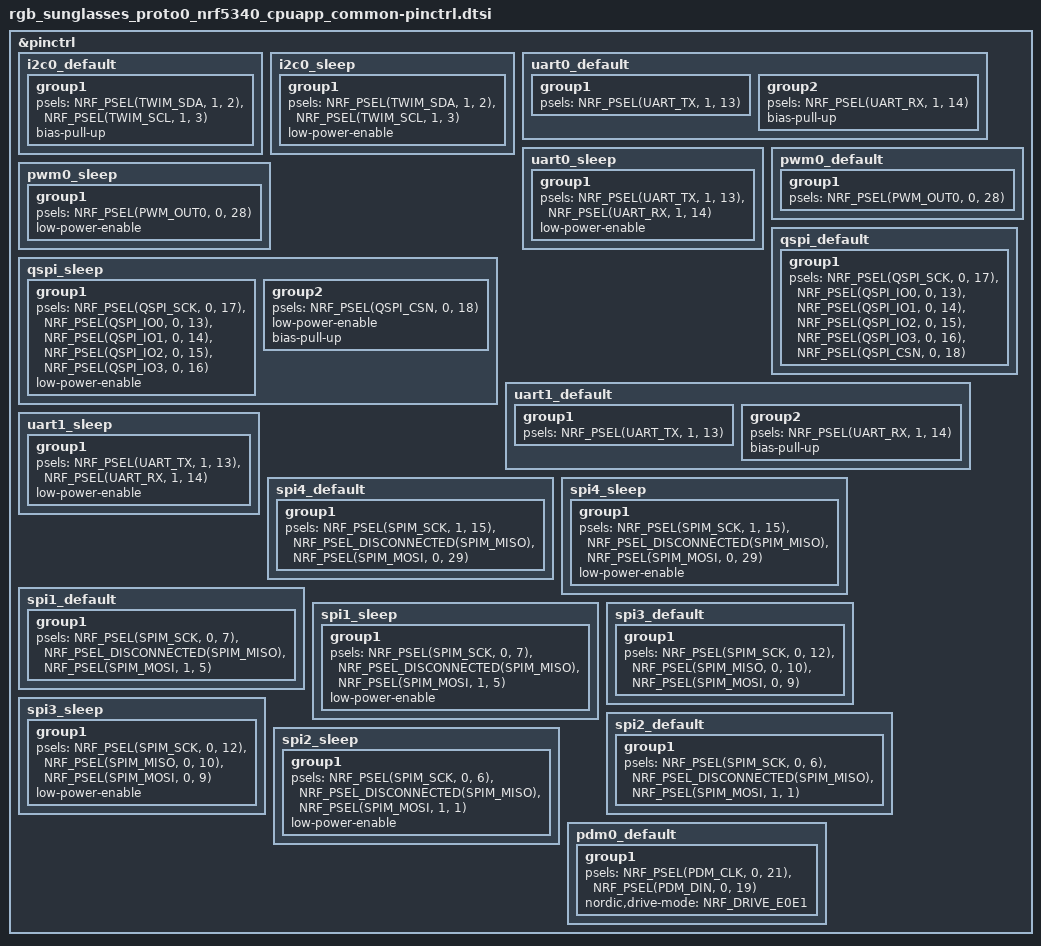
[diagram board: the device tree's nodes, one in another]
/*
 * Copyright (c) 2022 Nordic Semiconductor
 * SPDX-License-Identifier: Apache-2.0
 */

&pinctrl {
	i2c0_default: i2c0_default {
		group1 {
			psels = <NRF_PSEL(TWIM_SDA, 1, 2)>,
				<NRF_PSEL(TWIM_SCL, 1, 3)>;
			bias-pull-up;
		};
	};

	i2c0_sleep: i2c0_sleep {
		group1 {
			psels = <NRF_PSEL(TWIM_SDA, 1, 2)>,
				<NRF_PSEL(TWIM_SCL, 1, 3)>;
			low-power-enable;
		};
	};

	/* Physical UART: P1.13 = TX, P1.14 = RX (no hardware flow control on proto0) */
	uart0_default: uart0_default {
		group1 {
			psels = <NRF_PSEL(UART_TX, 1, 13)>;
		};
		group2 {
			psels = <NRF_PSEL(UART_RX, 1, 14)>;
			bias-pull-up;
		};
	};

	uart0_sleep: uart0_sleep {
		group1 {
			psels = <NRF_PSEL(UART_TX, 1, 13)>,
				<NRF_PSEL(UART_RX, 1, 14)>;
			low-power-enable;
		};
	};

	pwm0_default: pwm0_default {
		group1 {
			psels = <NRF_PSEL(PWM_OUT0, 0, 28)>;
		};
	};

	pwm0_sleep: pwm0_sleep {
		group1 {
			psels = <NRF_PSEL(PWM_OUT0, 0, 28)>;
			low-power-enable;
		};
	};

	qspi_default: qspi_default {
		group1 {
			psels = <NRF_PSEL(QSPI_SCK, 0, 17)>,
				<NRF_PSEL(QSPI_IO0, 0, 13)>,
				<NRF_PSEL(QSPI_IO1, 0, 14)>,
				<NRF_PSEL(QSPI_IO2, 0, 15)>,
				<NRF_PSEL(QSPI_IO3, 0, 16)>,
				<NRF_PSEL(QSPI_CSN, 0, 18)>;
		};
	};

	qspi_sleep: qspi_sleep {
		group1 {
			psels = <NRF_PSEL(QSPI_SCK, 0, 17)>,
				<NRF_PSEL(QSPI_IO0, 0, 13)>,
				<NRF_PSEL(QSPI_IO1, 0, 14)>,
				<NRF_PSEL(QSPI_IO2, 0, 15)>,
				<NRF_PSEL(QSPI_IO3, 0, 16)>;
			low-power-enable;
		};
		group2 {
			psels = <NRF_PSEL(QSPI_CSN, 0, 18)>;
			low-power-enable;
			bias-pull-up;
		};
	};

	/* Secondary UART forwarded to network core via gpio_fwd (P1.13 TX, P1.14 RX) */
	uart1_default: uart1_default {
		group1 {
			psels = <NRF_PSEL(UART_TX, 1, 13)>;
		};
		group2 {
			psels = <NRF_PSEL(UART_RX, 1, 14)>;
			bias-pull-up;
		};
	};

	uart1_sleep: uart1_sleep {
		group1 {
			psels = <NRF_PSEL(UART_TX, 1, 13)>,
				<NRF_PSEL(UART_RX, 1, 14)>;
			low-power-enable;
		};
	};

	spi4_default: spi4_default {
		group1 {
			psels = <NRF_PSEL(SPIM_SCK, 1, 15)>,
				/* MISO disconnected: led_strip_1 (WS2812) is output-only */
				<NRF_PSEL_DISCONNECTED(SPIM_MISO)>,
				<NRF_PSEL(SPIM_MOSI, 0, 29)>;
		};
	};

	spi4_sleep: spi4_sleep {
		group1 {
			psels = <NRF_PSEL(SPIM_SCK, 1, 15)>,
				<NRF_PSEL_DISCONNECTED(SPIM_MISO)>,
				<NRF_PSEL(SPIM_MOSI, 0, 29)>;
			low-power-enable;
		};
	};

	spi1_default: spi1_default {
		group1 {
			psels = <NRF_PSEL(SPIM_SCK, 0, 7)>,
				/* MISO disconnected: led_strip_0 (WS2812) is output-only; P0.19 is now PDM_DIN */
				<NRF_PSEL_DISCONNECTED(SPIM_MISO)>,
				<NRF_PSEL(SPIM_MOSI, 1, 5)>;
		};
	};

	spi1_sleep: spi1_sleep {
		group1 {
			psels = <NRF_PSEL(SPIM_SCK, 0, 7)>,
				<NRF_PSEL_DISCONNECTED(SPIM_MISO)>,
				<NRF_PSEL(SPIM_MOSI, 1, 5)>;
			low-power-enable;
		};
	};

	/* BMI270 IMU: SCK=P0.12, MISO=P0.10, MOSI=P0.09 */
	spi3_default: spi3_default {
		group1 {
			psels = <NRF_PSEL(SPIM_SCK,  0, 12)>,
				<NRF_PSEL(SPIM_MISO, 0, 10)>,
				<NRF_PSEL(SPIM_MOSI, 0,  9)>;
		};
	};

	spi3_sleep: spi3_sleep {
		group1 {
			psels = <NRF_PSEL(SPIM_SCK,  0, 12)>,
				<NRF_PSEL(SPIM_MISO, 0, 10)>,
				<NRF_PSEL(SPIM_MOSI, 0,  9)>;
			low-power-enable;
		};
	};

	/* Onboard LED strip (WS2812, output-only): MOSI=P1.01, SCK=P0.06 (freed from old bmic_wake) */
	spi2_default: spi2_default {
		group1 {
			psels = <NRF_PSEL(SPIM_SCK,  0, 6)>,
				<NRF_PSEL_DISCONNECTED(SPIM_MISO)>,
				<NRF_PSEL(SPIM_MOSI, 1, 1)>;
		};
	};

	spi2_sleep: spi2_sleep {
		group1 {
			psels = <NRF_PSEL(SPIM_SCK,  0, 6)>,
				<NRF_PSEL_DISCONNECTED(SPIM_MISO)>,
				<NRF_PSEL(SPIM_MOSI, 1, 1)>;
			low-power-enable;
		};
	};

	/* PDM microphone: CLK=P0.21, DIN=P0.19 */
	pdm0_default: pdm0_default {
		group1 {
			psels = <NRF_PSEL(PDM_CLK, 0, 21)>,
				<NRF_PSEL(PDM_DIN, 0, 19)>;

			nordic,drive-mode = < NRF_DRIVE_E0E1 >;
		};
	};

};
